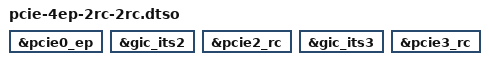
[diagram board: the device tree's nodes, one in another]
// SPDX-License-Identifier: (GPL-2.0+ OR MIT)
/*
 * Copyright (c) 2025 SiMa ai
 *
 * Overlay for 4-lane Endpoint, 2-lane(rc2), 2-lane(rc3) PCIe Root Complex
 */

/dts-v1/;
/plugin/;

&pcie0_ep {
        status = "okay";
};

&gic_its2 {
        status = "okay";
};

&pcie2_rc {
        status = "okay";
};

&gic_its3 {
        status = "okay";
};

&pcie3_rc {
        status = "okay";
};
